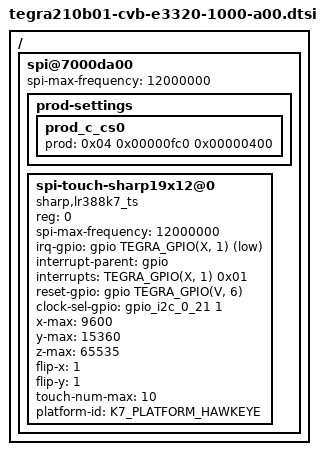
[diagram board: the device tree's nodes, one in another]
/*
 * Copyright (c) 2017, NVIDIA CORPORATION.  All rights reserved.
 *
 * This program is free software; you can redistribute it and/or modify
 * it under the terms of the GNU General Public License as published by
 * the Free Software Foundation; either version 2 of the License, or
 * (at your option) any later version.
 *
 * This program is distributed in the hope that it will be useful, but WITHOUT
 * ANY WARRANTY; without even the implied warranty of MERCHANTABILITY or
 * FITNESS FOR A PARTICULAR PURPOSE.  See the GNU General Public License for
 * more details.
 *
 * You should have received a copy of the GNU General Public License
 * along with this program.  If not, see <http://www.gnu.org/licenses/>.
 */

#include <dt-bindings/gpio/tegra-gpio.h>
#include <dt-bindings/spi/lr388k7_platform.h>
/ {
	spi@7000da00 {
		status = "okay";
		spi-max-frequency = <12000000>;
		prod-settings {
			prod_c_cs0 {
			    prod = <0x04 0x00000fc0 0x00000400>;
			};
		};
		spi-touch-sharp19x12@0 {
			status = "okay";
			compatible = "sharp,lr388k7_ts";
			reg = <0>; /* spi chip select 0 */
			spi-max-frequency = <12000000>;
			irq-gpio = <&gpio TEGRA_GPIO(X, 1) 0x01>; /* GPIO_PX1 */
			interrupt-parent = <&gpio>;
			interrupts = <TEGRA_GPIO(X, 1) 0x01>; /* GPIO_PX1 */
			reset-gpio = <&gpio TEGRA_GPIO(V, 6) 0>; /* GPIO_PV6 */
			clock-sel-gpio = <&gpio_i2c_0_21 1 0>; /* tca6408 7h21 pin1 */
			x-max = <9600>;
			y-max = <15360>;
			z-max = <65535>;
			flip-x = <1>;
			flip-y = <1>;
			touch-num-max = <10>;
			platform-id = <K7_PLATFORM_HAWKEYE>;
		};
	};
};
